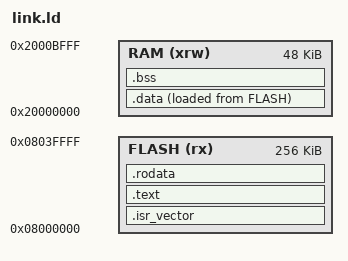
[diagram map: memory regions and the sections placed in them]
/* Linker script for STM32F103RCT6 (256K Flash, 48K RAM) */

MEMORY
{
  RAM    (xrw)   : ORIGIN = 0x20000000, LENGTH = 48K
  FLASH  (rx)    : ORIGIN = 0x08000000, LENGTH = 256K
}

SECTIONS
{
  .isr_vector :
  {
    . = ALIGN(4);
    KEEP(*(.isr_vector))
    . = ALIGN(4);
  } >FLASH

  .text :
  {
    . = ALIGN(4);
    *(.text)
    *(.text*)
    . = ALIGN(4);
    _etext = .;
  } >FLASH

  .rodata :
  {
    . = ALIGN(4);
    *(.rodata)
    *(.rodata*)
    . = ALIGN(4);
  } >FLASH

  _sidata = LOADADDR(.data);

  .data :
  {
    . = ALIGN(4);
    _sdata = .;
    *(.data)
    *(.data*)
    . = ALIGN(4);
    _edata = .;
  } >RAM AT> FLASH

  .bss :
  {
    . = ALIGN(4);
    _sbss = .;
    __bss_start__ = _sbss;
    *(.bss)
    *(.bss*)
    *(COMMON)
    . = ALIGN(4);
    _ebss = .;
    __bss_end__ = _ebss;
  } >RAM
}
